AUTOSAR XML (schema 4-2-2)
package /ComponentTypes
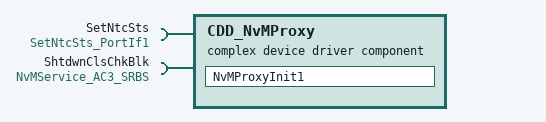
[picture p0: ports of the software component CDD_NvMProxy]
  complex device driver sw component type CDD_NvMProxy
    require port SetNtcSts: client-com-spec=Oper, required-interface=SetNtcSts_PortIf1
    require port ShtdwnClsChkBlk: required-com-specs=[EraseBlock, GetErrorStatus, InvalidateNvBlock, ReadBlock, SetRamBlockStatus, WriteBlock], required-interface=NvMService_AC3_SRBS
    behavior CDD_NvMProxy_InternalBehavior
      ar-typed-per-instance-memorys:
        5 x data:
          BlkFltTbl: sw-calibration-access=READ-ONLY, type=Ary1D_BlkFltTblRec1_5
          CmdRtnBuf: type=Ary1D_CmdRtnBufRec1_NvMProxy1
          NvmBlkActv: sw-calibration-access=READ-ONLY, type=Ary1D_boolean_NvMProxy1
          NvmStsCollctd: sw-calibration-access=READ-ONLY, type=boolean
          ShtdwnClsChk: sw-calibration-access=READ-ONLY, type=uint32
      init event NvMProxy_InitEvent: start-on-event=NvMProxyInit1
      runnable NvMProxyInit1
        sync call SC_SetNtcSts_Oper: operation=SetNtcSts.Oper, timeout=0
      swc service dependency ShtdwnClsChkBlk: assigned-datas=role-based-data-assignment={role=ramBlock, used-data-element=ShtdwnClsChk}, assigned-ports=role-based-port-assignment={port-prototype=ShtdwnClsChkBlk, role=NvMService_AC3_SRBS}
        service-needs:
          nv block needs ShtdwnClsChkBlk: n-data-sets=0, ram-block-status-control=API, readonly=false, reliability=ERROR-DETECTION, resistant-to-changed-sw=true, restore-at-start=true, store-at-shutdown=true, write-only-once=false, writing-frequency=0, writing-priority=LOW
  swc implementation CDD_NvMProxy_Implementation: behavior=CDD_NvMProxy_InternalBehavior
    code-descriptors:
      code Default: artifact-descriptors=autosar-engineering-object={short-label=Default, category=SWSRC}
